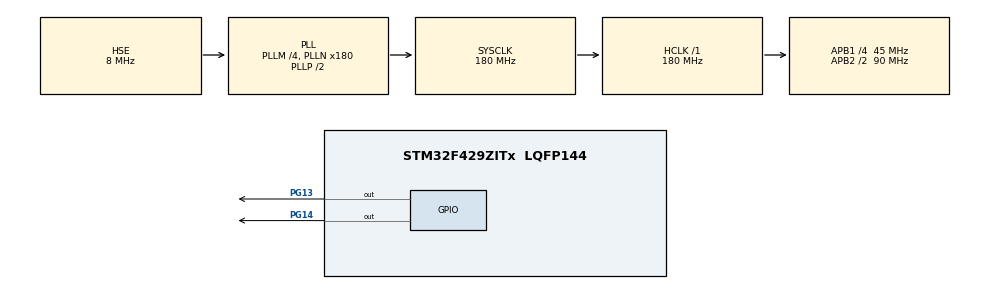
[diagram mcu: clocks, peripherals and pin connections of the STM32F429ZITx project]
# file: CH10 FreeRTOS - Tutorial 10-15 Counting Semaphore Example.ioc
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FREERTOS.Tasks01=defaultTask,24,128,StartDefaultTask,Default,NULL,Dynamic,NULL,NULL;myTask02,32,128,StartTask02,Default,NULL,Dynamic,NULL,NULL;myTask03,33,128,StartTask03,Default,NULL,Dynamic,NULL,NULL
FREERTOS.configUSE_NEWLIB_REENTRANT=1
Mcu.Family=STM32F4
Mcu.Name=STM32F429ZITx
Mcu.Package=LQFP144
NVIC.PriorityGroup=NVIC_PRIORITYGROUP_4
NVIC.TIM2_IRQn=true\:5\:0\:true\:false\:true\:true\:true\:true\:true
NVIC.TIM6_DAC_IRQn=true\:15\:0\:false\:false\:true\:false\:false\:true\:true
NVIC.TimeBase=TIM6_DAC_IRQn
NVIC.TimeBaseIP=TIM6
PG13.Signal=GPIO_Output
PG14.Signal=GPIO_Output
PH0/OSC_IN.Mode=HSE-External-Oscillator
PH0/OSC_IN.Signal=RCC_OSC_IN
PH1/OSC_OUT.Mode=HSE-External-Oscillator
PH1/OSC_OUT.Signal=RCC_OSC_OUT
ProjectManager.HeapSize=0x200
ProjectManager.StackSize=0x400
ProjectManager.TargetToolchain=STM32CubeIDE
RCC.48MHZClocksFreq_Value=51428571.428571425
RCC.AHBFreq_Value=180000000
RCC.APB1CLKDivider=RCC_HCLK_DIV4
RCC.APB1Freq_Value=45000000
RCC.APB1TimFreq_Value=90000000
RCC.APB2CLKDivider=RCC_HCLK_DIV2
RCC.APB2Freq_Value=90000000
RCC.APB2TimFreq_Value=180000000
RCC.CortexFreq_Value=180000000
RCC.HCLKFreq_Value=180000000
RCC.HSE_VALUE=8000000
RCC.HSI_VALUE=16000000
RCC.LSE_VALUE=32768
RCC.PLLM=4
RCC.PLLN=180
RCC.PLLQ=7
RCC.PLLSourceVirtual=RCC_PLLSOURCE_HSE
RCC.SYSCLKFreq_VALUE=180000000
RCC.SYSCLKSource=RCC_SYSCLKSOURCE_PLLCLK
RCC.VCOOutputFreq_Value=360000000
TIM2.Period=10000-1
TIM2.Prescaler=9000-1
VP_FREERTOS_VS_CMSIS_V2.Mode=CMSIS_V2
VP_SYS_VS_tim6.Mode=TIM6
VP_TIM2_VS_ClockSourceINT.Mode=Internal
board=STM32F429I-DISC1

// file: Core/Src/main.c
/* USER CODE BEGIN Header */
/**
  ******************************************************************************
  * @file           : main.c
  * @brief          : Main program body
  ******************************************************************************
  * @attention
  *
  * Copyright (c) 2024 STMicroelectronics.
  * All rights reserved.
  *
  * This software is licensed under terms that can be found in the LICENSE file
  * in the root directory of this software component.
  * If no LICENSE file comes with this software, it is provided AS-IS.
  *
  ******************************************************************************
  */

	/***************************** Tutorial Tags ******************************
		 FreeRTOS
		 Binary semaphore
		 Task management (priority, state)
		 GPIO output
	 **************************************************************************/

	/* 10.5 Binary semaphore in FreeRTOS: **************************************
	 * Tutorial -10-15: The counting semaphore example in FreeRTOS
	 *
	WARNING: CODE is written mostly without help of CubeMX. If you regenerate code using CubeMX
	you will lose the code here.

    In this tutorial, we benefit from the counting
	semaphore to control three tasks with different priorities. myTask03 has the highest
	priority and fills the array arr (with 10 elements) from 0 to 9. myTask02 has
	the second highest priority and it multiplies each element of the array arr by
	5. Finally, the default task has the lowest priority and it prints the elements of
	array arr. Each task waits for a semaphore token. Therefore, we set the period
	of Timer 2 to 1 s to generate an interrupt. Three semaphore tokens are released by
	the Timer 2 callback function. Hence, every time an interrupt is generated by Timer
	2, myTask03, myTask02, and the default task are called based on their priority. To
	note here, the semaphore number is initially reset by the function osSemaphoreNew.
	Therefore, no operation is done unless the timer interrupt comes.We should modify
	ITM properties as explained in Sect. 3.4.1.1 to observe printing results in this
	example.

	***************************************************************************/

/* USER CODE END Header */
#include "main.h"
#include "cmsis_os.h"

/* USER CODE BEGIN Includes */
#include "stdio.h"
/* USER CODE END Includes */

/* USER CODE BEGIN PD */
# define lenarr 10
/* USER CODE END PD */

TIM_HandleTypeDef htim2;

/* Definitions for defaultTask */
osThreadId_t defaultTaskHandle;
const osThreadAttr_t defaultTask_attributes = {
  .name = "defaultTask",
  .stack_size = 128 * 4,
  .priority = (osPriority_t) osPriorityNormal,
};
/* Definitions for myTask02 */
osThreadId_t myTask02Handle;
const osThreadAttr_t myTask02_attributes = {
  .name = "myTask02",
  .stack_size = 128 * 4,
  .priority = (osPriority_t) osPriorityAboveNormal,
};
/* Definitions for myTask03 */
osThreadId_t myTask03Handle;
const osThreadAttr_t myTask03_attributes = {
  .name = "myTask03",
  .stack_size = 128 * 4,
  .priority = (osPriority_t) osPriorityHigh,
};

/*Define a semaphore*/
osSemaphoreId_t myCountingSem01Handle;

const osSemaphoreAttr_t myCountingSem01_attributes = {
		.name = "myCountingSem01",
};
/* USER CODE BEGIN PV */

uint8_t arr [10];

uint32_t count;

/* USER CODE END PV */

void SystemClock_Config(void);
static void MX_GPIO_Init(void);
static void MX_TIM2_Init(void);
void StartDefaultTask(void *argument);
void StartTask02(void *argument);
void StartTask03(void *argument);

void fillarray (uint8_t arr[], uint8_t);
void multiplyarray (uint8_t arr[], uint8_t);
void printarray (uint8_t arr[], uint8_t);

/* USER CODE BEGIN 0 */
/*Function needed to use printf on CONSOLE*/
int _write(int file, char *ptr, int len){
	  int i = 0;
	  for (i=0; i<len; i++)
		  ITM_SendChar((*ptr++));
	  return len;
}
/* USER CODE END 0 */

int main(void)
{

  /* MCU Configuration--------------------------------------------------------*/

  /* Reset of all peripherals, Initializes the Flash interface and the Systick. */
  HAL_Init();

  /* Configure the system clock */
  SystemClock_Config();

  /* Initialize all configured peripherals */
  MX_GPIO_Init();
  MX_TIM2_Init();
  /* USER CODE BEGIN 2 */
  printf("PROGRAM START \n\r");

  /*Start Timer 2 in interrupt mode (Generate interrupt every second)*/
  HAL_TIM_Base_Start_IT(&htim2);
  /* USER CODE END 2 */

  /* Init scheduler */
  osKernelInitialize();

  /* USER CODE BEGIN RTOS_SEMAPHORES */

  //count = osSemaphoreGetCount(myCountingSem01Handle);
  /* USER CODE END RTOS_SEMAPHORES */

  /* Create the thread(s) */
  /* creation of defaultTask */
  defaultTaskHandle = osThreadNew(StartDefaultTask, NULL, &defaultTask_attributes);

  /* creation of myTask02 */
  myTask02Handle = osThreadNew(StartTask02, NULL, &myTask02_attributes);

  /* creation of myTask03 */
  myTask03Handle = osThreadNew(StartTask03, NULL, &myTask03_attributes);

  /* Start scheduler */
  osKernelStart();

  /* We should never get here as control is now taken by the scheduler */
  /* Infinite loop */
  while (1)
  {

  }
}

void SystemClock_Config(void)
{
  RCC_OscInitTypeDef RCC_OscInitStruct = {0};
  RCC_ClkInitTypeDef RCC_ClkInitStruct = {0};

  /** Configure the main internal regulator output voltage
  */
  __HAL_RCC_PWR_CLK_ENABLE();
  __HAL_PWR_VOLTAGESCALING_CONFIG(PWR_REGULATOR_VOLTAGE_SCALE1);

  /** Initializes the RCC Oscillators according to the specified parameters
  * in the RCC_OscInitTypeDef structure.
  */
  RCC_OscInitStruct.OscillatorType = RCC_OSCILLATORTYPE_HSE;
  RCC_OscInitStruct.HSEState = RCC_HSE_ON;
  RCC_OscInitStruct.PLL.PLLState = RCC_PLL_ON;
  RCC_OscInitStruct.PLL.PLLSource = RCC_PLLSOURCE_HSE;
  RCC_OscInitStruct.PLL.PLLM = 4;
  RCC_OscInitStruct.PLL.PLLN = 180;
  RCC_OscInitStruct.PLL.PLLP = RCC_PLLP_DIV2;
  RCC_OscInitStruct.PLL.PLLQ = 7;
  if (HAL_RCC_OscConfig(&RCC_OscInitStruct) != HAL_OK)
  {
    Error_Handler();
  }

  /** Activate the Over-Drive mode
  */
  if (HAL_PWREx_EnableOverDrive() != HAL_OK)
  {
    Error_Handler();
  }

  /** Initializes the CPU, AHB and APB buses clocks
  */
  RCC_ClkInitStruct.ClockType = RCC_CLOCKTYPE_HCLK|RCC_CLOCKTYPE_SYSCLK
                              |RCC_CLOCKTYPE_PCLK1|RCC_CLOCKTYPE_PCLK2;
  RCC_ClkInitStruct.SYSCLKSource = RCC_SYSCLKSOURCE_PLLCLK;
  RCC_ClkInitStruct.AHBCLKDivider = RCC_SYSCLK_DIV1;
  RCC_ClkInitStruct.APB1CLKDivider = RCC_HCLK_DIV4;
  RCC_ClkInitStruct.APB2CLKDivider = RCC_HCLK_DIV2;

  if (HAL_RCC_ClockConfig(&RCC_ClkInitStruct, FLASH_LATENCY_5) != HAL_OK)
  {
    Error_Handler();
  }
}

static void MX_TIM2_Init(void)
{

  TIM_ClockConfigTypeDef sClockSourceConfig = {0};
  TIM_MasterConfigTypeDef sMasterConfig = {0};

  htim2.Instance = TIM2;
  htim2.Init.Prescaler = 9000-1;
  htim2.Init.CounterMode = TIM_COUNTERMODE_UP;
  htim2.Init.Period = 10000-1;
  htim2.Init.ClockDivision = TIM_CLOCKDIVISION_DIV1;
  htim2.Init.AutoReloadPreload = TIM_AUTORELOAD_PRELOAD_DISABLE;
  if (HAL_TIM_Base_Init(&htim2) != HAL_OK)
  {
    Error_Handler();
  }
  sClockSourceConfig.ClockSource = TIM_CLOCKSOURCE_INTERNAL;
  if (HAL_TIM_ConfigClockSource(&htim2, &sClockSourceConfig) != HAL_OK)
  {
    Error_Handler();
  }
  sMasterConfig.MasterOutputTrigger = TIM_TRGO_RESET;
  sMasterConfig.MasterSlaveMode = TIM_MASTERSLAVEMODE_DISABLE;
  if (HAL_TIMEx_MasterConfigSynchronization(&htim2, &sMasterConfig) != HAL_OK)
  {
    Error_Handler();
  }

}

static void MX_GPIO_Init(void)
{
  GPIO_InitTypeDef GPIO_InitStruct = {0};

  /* GPIO Ports Clock Enable */
  __HAL_RCC_GPIOH_CLK_ENABLE();
  __HAL_RCC_GPIOG_CLK_ENABLE();

  /*Configure GPIO pin Output Level */
  HAL_GPIO_WritePin(GPIOG, GPIO_PIN_13|GPIO_PIN_14, GPIO_PIN_RESET);

  /*Configure GPIO pins : PG13 PG14 */
  GPIO_InitStruct.Pin = GPIO_PIN_13|GPIO_PIN_14;
  GPIO_InitStruct.Mode = GPIO_MODE_OUTPUT_PP;
  GPIO_InitStruct.Pull = GPIO_NOPULL;
  GPIO_InitStruct.Speed = GPIO_SPEED_FREQ_LOW;
  HAL_GPIO_Init(GPIOG, &GPIO_InitStruct);

}

void StartDefaultTask(void *argument)
{
  /* USER CODE BEGIN 5 */

  /* Infinite loop */
  for(;;)
  {
	  osSemaphoreAcquire(myCountingSem01Handle, osWaitForever);
	  printarray (arr, lenarr);
	  osDelay(1000);
  }
  /* USER CODE END 5 */
}

void StartTask02(void *argument)
{
  /* USER CODE BEGIN StartTask02 */

  /* Infinite loop */
  for(;;)
  {
	  osSemaphoreAcquire(myCountingSem01Handle, osWaitForever);
	  multiplyarray (arr, lenarr);
	  osDelay(1000);

  }
  /* USER CODE END StartTask02 */
}

void StartTask03(void *argument)
{
  /* USER CODE BEGIN StartTask03 */
  /* Infinite loop */
  for(;;)
  {
	  osSemaphoreAcquire(myCountingSem01Handle, osWaitForever);
	  fillarray (arr, lenarr);
	  osDelay(1000);
  }
  /* USER CODE END StartTask03 */
}

/*Define functions*/

void fillarray (uint8_t arr[], uint8_t len){
	for (int i = 0; i < len; ++i) {
		arr[i] = i;
	}
}

void multiplyarray (uint8_t arr[], uint8_t len){
	for (int i = 0; i < len; ++i) {
		arr[i] = arr[i]*5;
	}
}

void printarray (uint8_t arr[], uint8_t len){
	printf("Printing array:\n");
	for (int i = 0; i < len; ++i) {

		printf("%u\n", arr[i]);
	}
}

void HAL_TIM_PeriodElapsedCallback(TIM_HandleTypeDef *htim)
{
	if (htim->Instance == TIM6) {
		HAL_IncTick();
	}
	else if (htim->Instance == TIM2) {

		printf("Release all tokens \n\r");
		//osSemaphoreRelease(myCountingSem01Handle);
		//osSemaphoreRelease(myCountingSem01Handle);
		//osSemaphoreRelease(myCountingSem01Handle);
        // Create the semaphore with the required number of tokens
		myCountingSem01Handle = osSemaphoreNew(3, 3, & myCountingSem01_attributes);

	}

}

void Error_Handler(void)
{
  __disable_irq();
  while (1)
  {
  }
}
